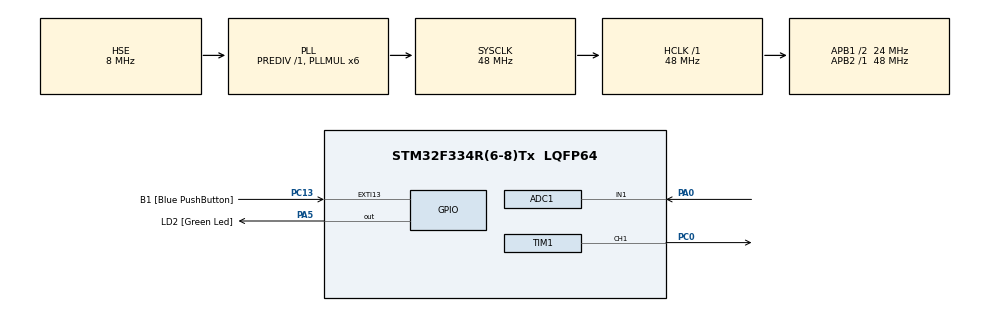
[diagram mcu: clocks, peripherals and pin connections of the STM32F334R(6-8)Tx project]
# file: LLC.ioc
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ADC1.Channel-0\#ChannelRegularConversion=ADC_CHANNEL_1
ADC1.ContinuousConvMode=ENABLE
ADC1.DMAContinuousRequests=ENABLE
ADC1.NbrOfConversionFlag=1
ADC1.Offset-0\#ChannelRegularConversion=0
ADC1.OffsetNumber-0\#ChannelRegularConversion=ADC_OFFSET_NONE
ADC1.Rank-0\#ChannelRegularConversion=1
ADC1.SamplingTime-0\#ChannelRegularConversion=ADC_SAMPLETIME_1CYCLE_5
ADC1.SamplingTimeOPAMP-0\#ChannelRegularConversion=ADC_SAMPLETIME_61CYCLES_5
ADC1.SubFamily=STM32F334x8
ADC1.master=1
Dma.ADC1.0.Direction=DMA_PERIPH_TO_MEMORY
Dma.ADC1.0.Instance=DMA1_Channel1
Dma.ADC1.0.MemDataAlignment=DMA_MDATAALIGN_WORD
Dma.ADC1.0.MemInc=DMA_MINC_ENABLE
Dma.ADC1.0.Mode=DMA_NORMAL
Dma.ADC1.0.PeriphDataAlignment=DMA_PDATAALIGN_WORD
Dma.ADC1.0.PeriphInc=DMA_PINC_DISABLE
Dma.ADC1.0.Priority=DMA_PRIORITY_LOW
Dma.Request0=ADC1
Mcu.Family=STM32F3
Mcu.Name=STM32F334R(6-8)Tx
Mcu.Package=LQFP64
NVIC.DMA1_Channel1_IRQn=true\:0\:0\:false\:false\:true\:false\:true
NVIC.PriorityGroup=NVIC_PRIORITYGROUP_0
PA0.Mode=IN1-Single-Ended
PA0.Signal=ADC1_IN1
PA13.GPIO_Label=TMS
PA13.Mode=Serial_Wire
PA13.Signal=SYS_JTMS-SWDIO
PA14.GPIO_Label=TCK
PA14.Mode=Serial_Wire
PA14.Signal=SYS_JTCK-SWCLK
PA2.GPIO_Label=USART_TX
PA2.Signal=USART2_TX
PA3.GPIO_Label=USART_RX
PA3.Signal=USART2_RX
PA5.GPIO_Label=LD2 [Green Led]
PA5.Signal=GPIO_Output
PB3.GPIO_Label=SWO
PB3.Signal=SYS_JTDO-TRACESWO
PC0.Signal=S_TIM1_CH1
PC13.GPIO_Label=B1 [Blue PushButton]
PC13.GPIO_ModeDefaultEXTI=GPIO_MODE_IT_FALLING
PC13.Signal=GPXTI13
PC14\ /\ OSC32_IN.Signal=RCC_OSC32_IN
PC15\ /\ OSC32_OUT.GPIO_Label=RCC_OSC32_OUT
PC15\ /\ OSC32_OUT.Signal=RCC_OSC32_OUT
PF0\ /\ OSC_IN.Mode=HSE-External-Oscillator
PF0\ /\ OSC_IN.Signal=RCC_OSC_IN
PF1\ /\ OSC_OUT.Mode=HSE-External-Oscillator
PF1\ /\ OSC_OUT.Signal=RCC_OSC_OUT
ProjectManager.HeapSize=0x200
ProjectManager.StackSize=0x400
ProjectManager.TargetToolchain=STM32CubeIDE
RCC.AHBFreq_Value=48000000
RCC.APB1CLKDivider=RCC_HCLK_DIV2
RCC.APB1Freq_Value=24000000
RCC.APB1TimFreq_Value=48000000
RCC.APB2Freq_Value=48000000
RCC.APB2TimFreq_Value=48000000
RCC.CortexFreq_Value=48000000
RCC.FLatency-AdvancedSettings=FLASH_LATENCY_1
RCC.HCLKFreq_Value=48000000
RCC.HSE_VALUE=8000000
RCC.HSI_VALUE=8000000
RCC.PLLMUL=RCC_PLL_MUL6
RCC.PLLSourceVirtual=RCC_PLLSOURCE_HSE
RCC.SYSCLKFreq_VALUE=48000000
RCC.SYSCLKSourceVirtual=RCC_SYSCLKSOURCE_PLLCLK
SH.S_TIM1_CH1.0=TIM1_CH1,PWM Generation1 CH1
TIM1.Channel-PWM\ Generation1\ CH1=TIM_CHANNEL_1
TIM1.Period=47799
TIM1.Prescaler=0
TIM1.Pulse-PWM\ Generation1\ CH1=50
board=NUCLEO-F334R8

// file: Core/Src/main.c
/* USER CODE BEGIN Header */
/**
  ******************************************************************************
  * @file           : main.c
  * @brief          : Main program body
  ******************************************************************************
  * @attention
  *
  * <h2><center>&copy; Copyright (c) 2022 STMicroelectronics.
  * All rights reserved.</center></h2>
  *
  * This software component is licensed by ST under BSD 3-Clause license,
  * the "License"; You may not use this file except in compliance with the
  * License. You may obtain a copy of the License at:
  *                        opensource.org/licenses/BSD-3-Clause
  *
  ******************************************************************************
  */
/* USER CODE END Header */
#include "main.h"

ADC_HandleTypeDef hadc1;
DMA_HandleTypeDef hdma_adc1;
TIM_HandleTypeDef htim1;

/* USER CODE BEGIN PV */
#include "formula.h"

uint32_t adc_value[2];
uint16_t period_value = 0 ;

uint16_t TIM_SET_PERIOD(uint16_t *PERIOD_VALUE){
	htim1.Init.Period = *PERIOD_VALUE;
	return *PERIOD_VALUE;
}

/* USER CODE END PV */

void SystemClock_Config(void);
static void MX_GPIO_Init(void);
static void MX_DMA_Init(void);
static void MX_ADC1_Init(void);
static void MX_TIM1_Init(void);

int main(void)
{

  /* MCU Configuration--------------------------------------------------------*/

  /* Reset of all peripherals, Initializes the Flash interface and the Systick. */
  HAL_Init();

  /* Configure the system clock */
  SystemClock_Config();

  /* Initialize all configured peripherals */
  MX_GPIO_Init();
  MX_DMA_Init();
  MX_ADC1_Init();
  MX_TIM1_Init();
  /* USER CODE BEGIN 2 */

  HAL_ADC_Start_DMA(&hadc1, adc_value,1);
  HAL_TIM_PWM_Start_IT(&htim1, TIM_CHANNEL_1);

  /* USER CODE END 2 */

  /* Infinite loop */
  while (1)
  {

    /* USER CODE BEGIN 3 */
    period_value = CALCULATOR(&adc_value);
    mapTimer(&period_value);
	TIM_SET_PERIOD(&period_value);
	//DELAY EKLENMELI MI ???????????????????????????????????????????????????????????????????????
  }
  /* USER CODE END 3 */
}

void SystemClock_Config(void)
{
  RCC_OscInitTypeDef RCC_OscInitStruct = {0};
  RCC_ClkInitTypeDef RCC_ClkInitStruct = {0};
  RCC_PeriphCLKInitTypeDef PeriphClkInit = {0};

  /** Initializes the RCC Oscillators according to the specified parameters
  * in the RCC_OscInitTypeDef structure.
  */
  RCC_OscInitStruct.OscillatorType = RCC_OSCILLATORTYPE_HSE;
  RCC_OscInitStruct.HSEState = RCC_HSE_ON;
  RCC_OscInitStruct.HSEPredivValue = RCC_HSE_PREDIV_DIV1;
  RCC_OscInitStruct.HSIState = RCC_HSI_ON;
  RCC_OscInitStruct.PLL.PLLState = RCC_PLL_ON;
  RCC_OscInitStruct.PLL.PLLSource = RCC_PLLSOURCE_HSE;
  RCC_OscInitStruct.PLL.PLLMUL = RCC_PLL_MUL6;
  if (HAL_RCC_OscConfig(&RCC_OscInitStruct) != HAL_OK)
  {
    Error_Handler();
  }
  /** Initializes the CPU, AHB and APB buses clocks
  */
  RCC_ClkInitStruct.ClockType = RCC_CLOCKTYPE_HCLK|RCC_CLOCKTYPE_SYSCLK
                              |RCC_CLOCKTYPE_PCLK1|RCC_CLOCKTYPE_PCLK2;
  RCC_ClkInitStruct.SYSCLKSource = RCC_SYSCLKSOURCE_PLLCLK;
  RCC_ClkInitStruct.AHBCLKDivider = RCC_SYSCLK_DIV1;
  RCC_ClkInitStruct.APB1CLKDivider = RCC_HCLK_DIV2;
  RCC_ClkInitStruct.APB2CLKDivider = RCC_HCLK_DIV1;

  if (HAL_RCC_ClockConfig(&RCC_ClkInitStruct, FLASH_LATENCY_1) != HAL_OK)
  {
    Error_Handler();
  }
  PeriphClkInit.PeriphClockSelection = RCC_PERIPHCLK_TIM1|RCC_PERIPHCLK_ADC12;
  PeriphClkInit.Adc12ClockSelection = RCC_ADC12PLLCLK_DIV1;
  PeriphClkInit.Tim1ClockSelection = RCC_TIM1CLK_HCLK;
  if (HAL_RCCEx_PeriphCLKConfig(&PeriphClkInit) != HAL_OK)
  {
    Error_Handler();
  }
}

static void MX_ADC1_Init(void)
{

  ADC_MultiModeTypeDef multimode = {0};
  ADC_ChannelConfTypeDef sConfig = {0};

  /** Common config
  */
  hadc1.Instance = ADC1;
  hadc1.Init.ClockPrescaler = ADC_CLOCK_ASYNC_DIV1;
  hadc1.Init.Resolution = ADC_RESOLUTION_12B;
  hadc1.Init.ScanConvMode = ADC_SCAN_DISABLE;
  hadc1.Init.ContinuousConvMode = ENABLE;
  hadc1.Init.DiscontinuousConvMode = DISABLE;
  hadc1.Init.ExternalTrigConvEdge = ADC_EXTERNALTRIGCONVEDGE_NONE;
  hadc1.Init.ExternalTrigConv = ADC_SOFTWARE_START;
  hadc1.Init.DataAlign = ADC_DATAALIGN_RIGHT;
  hadc1.Init.NbrOfConversion = 1;
  hadc1.Init.DMAContinuousRequests = ENABLE;
  hadc1.Init.EOCSelection = ADC_EOC_SINGLE_CONV;
  hadc1.Init.LowPowerAutoWait = DISABLE;
  hadc1.Init.Overrun = ADC_OVR_DATA_OVERWRITTEN;
  if (HAL_ADC_Init(&hadc1) != HAL_OK)
  {
    Error_Handler();
  }
  /** Configure the ADC multi-mode
  */
  multimode.Mode = ADC_MODE_INDEPENDENT;
  if (HAL_ADCEx_MultiModeConfigChannel(&hadc1, &multimode) != HAL_OK)
  {
    Error_Handler();
  }
  /** Configure Regular Channel
  */
  sConfig.Channel = ADC_CHANNEL_1;
  sConfig.Rank = ADC_REGULAR_RANK_1;
  sConfig.SingleDiff = ADC_SINGLE_ENDED;
  sConfig.SamplingTime = ADC_SAMPLETIME_1CYCLE_5;
  sConfig.OffsetNumber = ADC_OFFSET_NONE;
  sConfig.Offset = 0;
  if (HAL_ADC_ConfigChannel(&hadc1, &sConfig) != HAL_OK)
  {
    Error_Handler();
  }

}

static void MX_TIM1_Init(void)
{

  TIM_MasterConfigTypeDef sMasterConfig = {0};
  TIM_OC_InitTypeDef sConfigOC = {0};
  TIM_BreakDeadTimeConfigTypeDef sBreakDeadTimeConfig = {0};

  htim1.Instance = TIM1;
  htim1.Init.Prescaler = 0;
  htim1.Init.CounterMode = TIM_COUNTERMODE_UP;
  htim1.Init.Period = 47799;
  htim1.Init.ClockDivision = TIM_CLOCKDIVISION_DIV1;
  htim1.Init.RepetitionCounter = 0;
  htim1.Init.AutoReloadPreload = TIM_AUTORELOAD_PRELOAD_DISABLE;
  if (HAL_TIM_PWM_Init(&htim1) != HAL_OK)
  {
    Error_Handler();
  }
  sMasterConfig.MasterOutputTrigger = TIM_TRGO_RESET;
  sMasterConfig.MasterOutputTrigger2 = TIM_TRGO2_RESET;
  sMasterConfig.MasterSlaveMode = TIM_MASTERSLAVEMODE_DISABLE;
  if (HAL_TIMEx_MasterConfigSynchronization(&htim1, &sMasterConfig) != HAL_OK)
  {
    Error_Handler();
  }
  sConfigOC.OCMode = TIM_OCMODE_PWM1;
  sConfigOC.Pulse = 50;
  sConfigOC.OCPolarity = TIM_OCPOLARITY_HIGH;
  sConfigOC.OCNPolarity = TIM_OCNPOLARITY_HIGH;
  sConfigOC.OCFastMode = TIM_OCFAST_DISABLE;
  sConfigOC.OCIdleState = TIM_OCIDLESTATE_RESET;
  sConfigOC.OCNIdleState = TIM_OCNIDLESTATE_RESET;
  if (HAL_TIM_PWM_ConfigChannel(&htim1, &sConfigOC, TIM_CHANNEL_1) != HAL_OK)
  {
    Error_Handler();
  }
  sBreakDeadTimeConfig.OffStateRunMode = TIM_OSSR_DISABLE;
  sBreakDeadTimeConfig.OffStateIDLEMode = TIM_OSSI_DISABLE;
  sBreakDeadTimeConfig.LockLevel = TIM_LOCKLEVEL_OFF;
  sBreakDeadTimeConfig.DeadTime = 0;
  sBreakDeadTimeConfig.BreakState = TIM_BREAK_DISABLE;
  sBreakDeadTimeConfig.BreakPolarity = TIM_BREAKPOLARITY_HIGH;
  sBreakDeadTimeConfig.BreakFilter = 0;
  sBreakDeadTimeConfig.Break2State = TIM_BREAK2_DISABLE;
  sBreakDeadTimeConfig.Break2Polarity = TIM_BREAK2POLARITY_HIGH;
  sBreakDeadTimeConfig.Break2Filter = 0;
  sBreakDeadTimeConfig.AutomaticOutput = TIM_AUTOMATICOUTPUT_DISABLE;
  if (HAL_TIMEx_ConfigBreakDeadTime(&htim1, &sBreakDeadTimeConfig) != HAL_OK)
  {
    Error_Handler();
  }
  HAL_TIM_MspPostInit(&htim1);

}

static void MX_DMA_Init(void)
{

  /* DMA controller clock enable */
  __HAL_RCC_DMA1_CLK_ENABLE();

  /* DMA interrupt init */
  /* DMA1_Channel1_IRQn interrupt configuration */
  HAL_NVIC_SetPriority(DMA1_Channel1_IRQn, 0, 0);
  HAL_NVIC_EnableIRQ(DMA1_Channel1_IRQn);

}

static void MX_GPIO_Init(void)
{
  GPIO_InitTypeDef GPIO_InitStruct = {0};

  /* GPIO Ports Clock Enable */
  __HAL_RCC_GPIOC_CLK_ENABLE();
  __HAL_RCC_GPIOF_CLK_ENABLE();
  __HAL_RCC_GPIOA_CLK_ENABLE();
  __HAL_RCC_GPIOB_CLK_ENABLE();

  /*Configure GPIO pin Output Level */
  HAL_GPIO_WritePin(LD2_GPIO_Port, LD2_Pin, GPIO_PIN_RESET);

  /*Configure GPIO pin : B1_Pin */
  GPIO_InitStruct.Pin = B1_Pin;
  GPIO_InitStruct.Mode = GPIO_MODE_IT_FALLING;
  GPIO_InitStruct.Pull = GPIO_NOPULL;
  HAL_GPIO_Init(B1_GPIO_Port, &GPIO_InitStruct);

  /*Configure GPIO pins : USART_TX_Pin USART_RX_Pin */
  GPIO_InitStruct.Pin = USART_TX_Pin|USART_RX_Pin;
  GPIO_InitStruct.Mode = GPIO_MODE_AF_PP;
  GPIO_InitStruct.Pull = GPIO_NOPULL;
  GPIO_InitStruct.Speed = GPIO_SPEED_FREQ_HIGH;
  GPIO_InitStruct.Alternate = GPIO_AF7_USART2;
  HAL_GPIO_Init(GPIOA, &GPIO_InitStruct);

  /*Configure GPIO pin : LD2_Pin */
  GPIO_InitStruct.Pin = LD2_Pin;
  GPIO_InitStruct.Mode = GPIO_MODE_OUTPUT_PP;
  GPIO_InitStruct.Pull = GPIO_NOPULL;
  GPIO_InitStruct.Speed = GPIO_SPEED_FREQ_LOW;
  HAL_GPIO_Init(LD2_GPIO_Port, &GPIO_InitStruct);

}

void Error_Handler(void)
{
  __disable_irq();
  while (1)
  {
  }
}

/************************ (C) COPYRIGHT STMicroelectronics *****END OF FILE****/
